# WKUP_PRM register map
Vendor: Texas Instruments
Peripheral module from a debugger description file (folder omap4430).
Registers are 32-bit, access not given, reset 0x1 unless marked. A register's access mark holds for its fields unless they carry their own. Offsets are as the file gives them; lines under a group give offsets from that group; [hi:lo] are bit positions; {n}, {i} and the like mark numbered series; 'fields as' and 'values as' point back to an identical list; <NAME> marks a mode.

## WKUP_PRM
0x24 RM_WKUP_L4WKUP_CONTEXT — This register contains dedicated L4WKUP context statuses. [warm reset insensitive]
  [0] LOSTCONTEXT_DFF — Specify if DFF-based context has been lost due to a previous power transition or other reset source. (set upon assertion of WKUP_RST signal) (access RW W1toClr)
    0=Context has been maintained; 1=Context has been lost
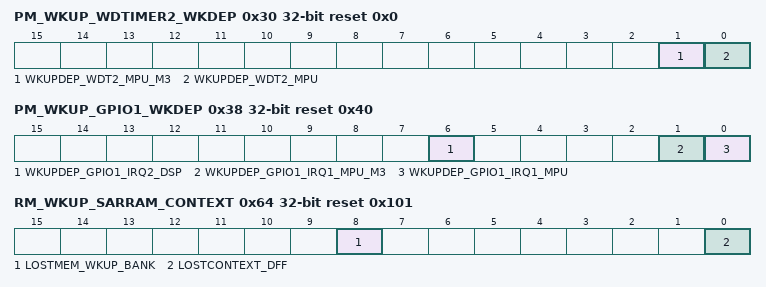
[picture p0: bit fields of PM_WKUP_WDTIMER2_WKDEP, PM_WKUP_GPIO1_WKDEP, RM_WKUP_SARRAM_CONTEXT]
0x30 PM_WKUP_WDTIMER2_WKDEP access per field reset 0x0 — This register controls wakeup dependency based on WDT2 service requests.
  [1] WKUPDEP_WDT2_MPU_M3 rw — Wakeup dependency from WDT2 module (softwareakeup signal) towards MPU_A3 + L3_2 + L3_1 + L4_CFG domains
    0=Dependency is disabled; 1=Dependency is enabled
  [0] WKUPDEP_WDT2_MPU rw — Wakeup dependency from WDT2 module (softwareakeup signal) towards MPU + L3_1 + L4_CFG domains
    0=Dependency is disabled; 1=Dependency is enabled
0x34 RM_WKUP_WDTIMER2_CONTEXT — This register contains dedicated WDT2 context statuses. [warm reset insensitive]
  fields as RM_WKUP_L4WKUP_CONTEXT
0x38 PM_WKUP_GPIO1_WKDEP reset 0x40 — This register controls wakeup dependency based on GPIO1 service requests.
  [6] WKUPDEP_GPIO1_IRQ2_DSP — Wakeup dependency from GPIO1 module (POINTRsoftwareAKEUP2 signal) towards DSP + L3_1 + L4_CFG domains (access R Rreturns1s)
    1=WKUPDEP_GPIO1_IRQ2_DSP_1_r (Dependency is enabled)
  [1] WKUPDEP_GPIO1_IRQ1_MPU_M3 rw — Wakeup dependency from GPIO1 module (POINTRsoftwareAKEUP1 signal) module towards MPU_A3 + L3_2 + L3_1 + L4_CFG domains
    0=Dependency is disabled; 1=Dependency is enabled
  [0] WKUPDEP_GPIO1_IRQ1_MPU rw — Wakeup dependency from GPIO1 module (POINTRsoftwareAKEUP1 signal) towards MPU + L3_1 + L4_CFG domains
    0=Dependency is disabled; 1=Dependency is enabled
0x3C RM_WKUP_GPIO1_CONTEXT — This register contains dedicated GPIO1 context statuses. [warm reset insensitive]
  fields as RM_WKUP_L4WKUP_CONTEXT
0x40 PM_WKUP_GPTIMER1_WKDEP — This register controls wakeup dependency based on TIMER1 service requests.
  [0] WKUPDEP_TIMER1_MPU — Wakeup dependency from TIMER1 module (softwareakeup signal) towards MPU + L3_1 + L4_CFG domains (access R Rreturns1s)
    1=WKUPDEP_TIMER1_MPU_1_r (Dependency is enabled)
0x44 RM_WKUP_GPTIMER1_CONTEXT — This register contains dedicated TIMER1 context statuses. [warm reset insensitive]
  fields as RM_WKUP_L4WKUP_CONTEXT
0x54 RM_WKUP_32KTIMER_CONTEXT — This register contains dedicated SYNCTIMER context statuses. [warm reset insensitive]
  [0] LOSTCONTEXT_DFF — Specify if DFF-based context has been lost due to a previous power transition or other reset source. (set upon assertion of WKUP_SYS_PWRON_RST signal) (access RW W1toClr)
    0=Context has been maintained; 1=Context has been lost
0x64 RM_WKUP_SARRAM_CONTEXT reset 0x101 — This register contains dedicated SARRAM context statuses. [warm reset insensitive]
  [8] LOSTMEM_WKUP_BANK — Specify if memory-based context in WKUP_BANK memory bank has been lost due to a previous global cold reset. (access RW W1toClr)
    0=Context has been maintained; 1=Context has been lost
  [0] LOSTCONTEXT_DFF — Specify if DFF-based context has been lost due to a previous power transition or other reset source. (set upon assertion of WKUP_RST signal) (access RW W1toClr)
    0=Context has been maintained; 1=Context has been lost
0x78 PM_WKUP_KEYBOARD_WKDEP — This register controls wakeup dependency based on KEYBOARD service requests.
  [0] WKUPDEP_KEYBOARD_MPU — Wakeup dependency from KEYBOARD module (softwareakeup signal) towards MPU + L3_1 + L4_CFG domains (access R Rreturns1s)
    1=WKUPDEP_KEYBOARD_MPU_1_r (Dependency is enabled)
0x7C RM_WKUP_KEYBOARD_CONTEXT — This register contains dedicated KEYBOARD context statuses. [warm reset insensitive]
  fields as RM_WKUP_L4WKUP_CONTEXT
